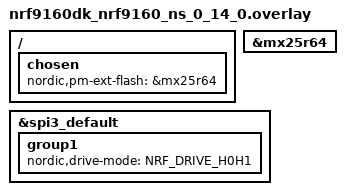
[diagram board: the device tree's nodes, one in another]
/*
 * Copyright (c) 2022 Nordic Semiconductor ASA
 *
 * SPDX-License-Identifier: LicenseRef-Nordic-5-Clause
 */

/ {
	chosen {
		nordic,pm-ext-flash = &mx25r64;
	};
};

/* External flash device is disabled by default */
&mx25r64 {
	status = "okay";
};

/* Enable high drive mode for the SPI3 pins to get a square signal at 8 MHz */
&spi3_default {
	group1 {
		nordic,drive-mode = <NRF_DRIVE_H0H1>;
	};
};
